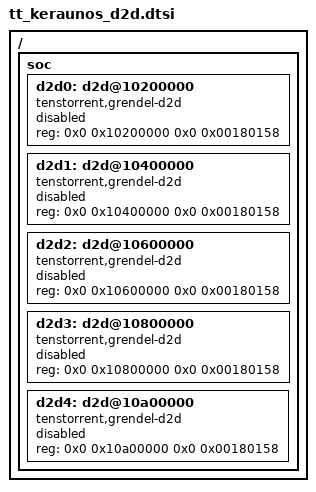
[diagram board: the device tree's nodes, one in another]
/*
 * Copyright (c) 2026 Tenstorrent AI ULC
 *
 * SPDX-License-Identifier: Apache-2.0
 */

/*
 * Keraunos carries five D2D tiles, one per HSIO tile, on the same 2 MB stride
 * and with the same internal layout as Mimir's two. Each sits behind its HSIO
 * tile, so a tile is only reachable once that HSIO tile is out of reset and
 * clocked.
 */

/ {
	soc {
		d2d0: d2d@10200000 {
			compatible = "tenstorrent,grendel-d2d";
			reg = <0x0 0x10200000 0x0 0x00180158>;
			status = "disabled";
		};

		d2d1: d2d@10400000 {
			compatible = "tenstorrent,grendel-d2d";
			reg = <0x0 0x10400000 0x0 0x00180158>;
			status = "disabled";
		};

		d2d2: d2d@10600000 {
			compatible = "tenstorrent,grendel-d2d";
			reg = <0x0 0x10600000 0x0 0x00180158>;
			status = "disabled";
		};

		d2d3: d2d@10800000 {
			compatible = "tenstorrent,grendel-d2d";
			reg = <0x0 0x10800000 0x0 0x00180158>;
			status = "disabled";
		};

		d2d4: d2d@10a00000 {
			compatible = "tenstorrent,grendel-d2d";
			reg = <0x0 0x10a00000 0x0 0x00180158>;
			status = "disabled";
		};
	};
};
